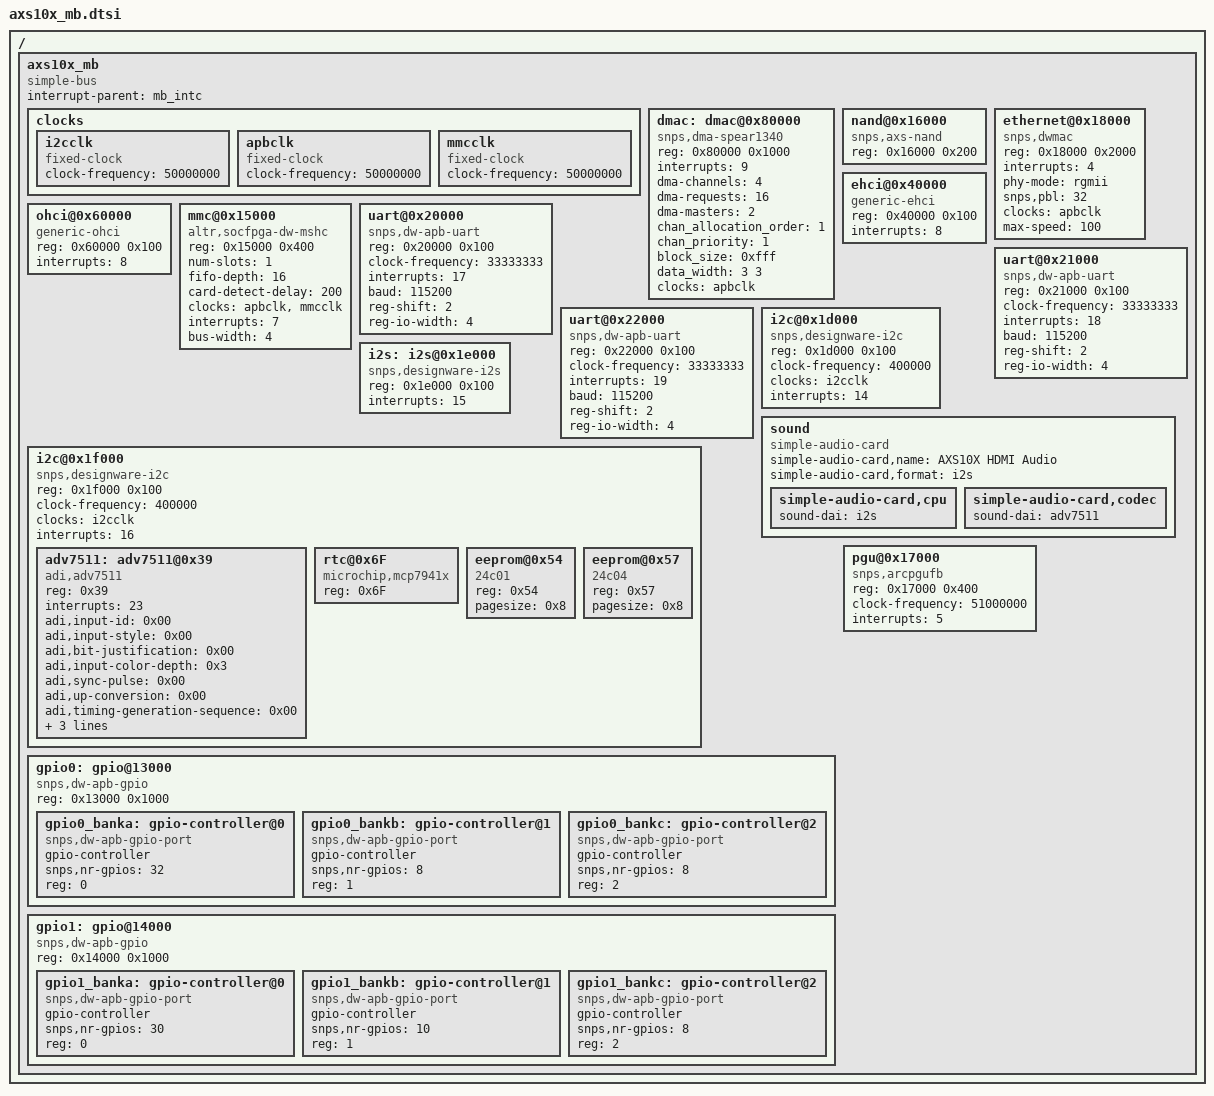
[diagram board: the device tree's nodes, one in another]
/*
 * Support for peripherals on the AXS10x mainboard
 *
 * Copyright (C) 2013-15 Synopsys, Inc. (www.synopsys.com)
 *
 * This program is free software; you can redistribute it and/or modify
 * it under the terms of the GNU General Public License version 2 as
 * published by the Free Software Foundation.
 */

/ {
	axs10x_mb {
		compatible = "simple-bus";
		#address-cells = <1>;
		#size-cells = <1>;
		ranges = <0x00000000 0xe0000000 0x10000000>;
		interrupt-parent = <&mb_intc>;

		clocks {
			i2cclk: i2cclk {
				compatible = "fixed-clock";
				clock-frequency = <50000000>;
				#clock-cells = <0>;
			};

			apbclk: apbclk {
				compatible = "fixed-clock";
				clock-frequency = <50000000>;
				#clock-cells = <0>;
			};

			mmcclk: mmcclk {
				compatible = "fixed-clock";
				clock-frequency = <50000000>;
				#clock-cells = <0>;
			};
		};

		dmac: dmac@0x80000 {
			compatible = "snps,dma-spear1340";
			reg = < 0x80000 0x1000 >;
			interrupts = < 9 >;
			dma-channels = < 4 >;
			dma-requests = < 16 >;
			dma-masters = < 2 >;
			#dma-cells = < 3 >;
			chan_allocation_order = <1>;
			chan_priority = <1>;
			block_size = <0xfff>;
			data_width = <3 3>;
			clocks = <&apbclk>;
			clock-names = "hclk";
		};

		nand@0x16000 {
			compatible = "snps,axs-nand";
			reg = < 0x16000 0x200 >;
		};

		ethernet@0x18000 {
			#interrupt-cells = <1>;
			compatible = "snps,dwmac";
			reg = < 0x18000 0x2000 >;
			interrupts = < 4 >;
			interrupt-names = "macirq";
			phy-mode = "rgmii";
			snps,pbl = < 32 >;
			clocks = <&apbclk>;
			clock-names = "stmmaceth";
			max-speed = <100>;
		};

		ehci@0x40000 {
			compatible = "generic-ehci";
			reg = < 0x40000 0x100 >;
			interrupts = < 8 >;
		};

		ohci@0x60000 {
			compatible = "generic-ohci";
			reg = < 0x60000 0x100 >;
			interrupts = < 8 >;
		};

		/*
		 * According to DW Mobile Storage databook it is required
		 * to use  "Hold Register" if card is enumerated in SDR12 or
		 * SDR25 modes.
		 *
		 * Utilization of "Hold Register" is already implemented via
		 * dw_mci_pltfm_prepare_command() which in its turn gets
		 * used through dw_mci_drv_data->prepare_command call-back.
		 * This call-back is used in Altera Socfpga platform and so
		 * we may reuse it saying that we're compatible with their
		 * "altr,socfpga-dw-mshc".
		 *
		 * Most probably "Hold Register" utilization is platform-
		 * independent requirement which means that single unified
		 * "snps,dw-mshc" should be enough for all users of DW MMC once
		 * dw_mci_pltfm_prepare_command() is used in generic platform
		 * code.
		 */
		mmc@0x15000 {
			compatible = "altr,socfpga-dw-mshc";
			reg = < 0x15000 0x400 >;
			num-slots = < 1 >;
			fifo-depth = < 16 >;
			card-detect-delay = < 200 >;
			clocks = <&apbclk>, <&mmcclk>;
			clock-names = "biu", "ciu";
			interrupts = < 7 >;
			bus-width = < 4 >;
		};

		uart@0x20000 {
			compatible = "snps,dw-apb-uart";
			reg = <0x20000 0x100>;
			clock-frequency = <33333333>;
			interrupts = <17>;
			baud = <115200>;
			reg-shift = <2>;
			reg-io-width = <4>;
		};

		uart@0x21000 {
			compatible = "snps,dw-apb-uart";
			reg = <0x21000 0x100>;
			clock-frequency = <33333333>;
			interrupts = <18>;
			baud = <115200>;
			reg-shift = <2>;
			reg-io-width = <4>;
		};

		/* UART muxed with USB data port (ttyS3) */
		uart@0x22000 {
			compatible = "snps,dw-apb-uart";
			reg = <0x22000 0x100>;
			clock-frequency = <33333333>;
			interrupts = <19>;
			baud = <115200>;
			reg-shift = <2>;
			reg-io-width = <4>;
		};

		i2c@0x1d000 {
			compatible = "snps,designware-i2c";
			reg = <0x1d000 0x100>;
			clock-frequency = <400000>;
			clocks = <&i2cclk>;
			interrupts = <14>;
		};

		i2s: i2s@0x1e000 {
			compatible = "snps,designware-i2s";
			reg = <0x1e000 0x100>;
			interrupts = <15>;
			#sound-dai-cells = <0>;
		};

		sound {
			compatible = "simple-audio-card";
			simple-audio-card,name = "AXS10X HDMI Audio";
			simple-audio-card,format = "i2s";
			simple-audio-card,cpu {
				sound-dai = <&i2s>;
			};
			simple-audio-card,codec {
				sound-dai = <&adv7511>;
			};
		};

		i2c@0x1f000 {
			compatible = "snps,designware-i2c";
			#address-cells = <1>;
			#size-cells = <0>;
			reg = <0x1f000 0x100>;
			clock-frequency = <400000>;
			clocks = <&i2cclk>;
			interrupts = <16>;

			adv7511: adv7511@0x39 {
				compatible = "adi,adv7511";
				reg = <0x39>;
				interrupts = <23>;
/*
 * Note: for reverse-bitorder and tmds-clock-inversion, of_property_read_bool
 * is used. This function returns true if the property is defined, even if
 * the value is 0!! Therefore, we do not add them here.
 * adi,reverse-bitorder = <0x00>;
 * adi,tdms-clock-inversion = <0x00>;
 */
				adi,input-id = <0x00>;
				adi,input-style = <0x00>;
				adi,bit-justification = <0x00>;
				adi,input-color-depth = <0x3>;
				adi,sync-pulse = <0x00>;
				adi,up-conversion = <0x00>;
				adi,timing-generation-sequence = <0x00>;
				adi,vsync-polarity = <0x02>;
				adi,hsync-polarity = <0x02>;
				adi,clock-delay = <0x03>;
				#sound-dai-cells = <0>;
			};

			rtc@0x6F {
				compatible = "microchip,mcp7941x";
				reg = <0x6F>;
			};

			eeprom@0x54{
				compatible = "24c01";
				reg = <0x54>;
				pagesize = <0x8>;
			};

			eeprom@0x57{
				compatible = "24c04";
				reg = <0x57>;
				pagesize = <0x8>;
			};
		};

		gpio0:gpio@13000 {
			compatible = "snps,dw-apb-gpio";
			reg = <0x13000 0x1000>;
			#address-cells = <1>;
			#size-cells = <0>;

			gpio0_banka: gpio-controller@0 {
				compatible = "snps,dw-apb-gpio-port";
				gpio-controller;
				#gpio-cells = <2>;
				snps,nr-gpios = <32>;
				reg = <0>;
			};

			gpio0_bankb: gpio-controller@1 {
				compatible = "snps,dw-apb-gpio-port";
				gpio-controller;
				#gpio-cells = <2>;
				snps,nr-gpios = <8>;
				reg = <1>;
			};

			gpio0_bankc: gpio-controller@2 {
				compatible = "snps,dw-apb-gpio-port";
				gpio-controller;
				#gpio-cells = <2>;
				snps,nr-gpios = <8>;
				reg = <2>;
			};
		};

		gpio1:gpio@14000 {
			compatible = "snps,dw-apb-gpio";
			reg = <0x14000 0x1000>;
			#address-cells = <1>;
			#size-cells = <0>;

			gpio1_banka: gpio-controller@0 {
				compatible = "snps,dw-apb-gpio-port";
				gpio-controller;
				#gpio-cells = <2>;
				snps,nr-gpios = <30>;
				reg = <0>;
			};

			gpio1_bankb: gpio-controller@1 {
				compatible = "snps,dw-apb-gpio-port";
				gpio-controller;
				#gpio-cells = <2>;
				snps,nr-gpios = <10>;
				reg = <1>;
			};

			gpio1_bankc: gpio-controller@2 {
				compatible = "snps,dw-apb-gpio-port";
				gpio-controller;
				#gpio-cells = <2>;
				snps,nr-gpios = <8>;
				reg = <2>;
			};
		};

		pgu@0x17000 {
			compatible = "snps,arcpgufb";
			reg = <0x17000 0x400>;
			clock-frequency = <51000000>; /* PGU'clock is initated in init function */
			interrupts = <5>;
		};
	};
};
